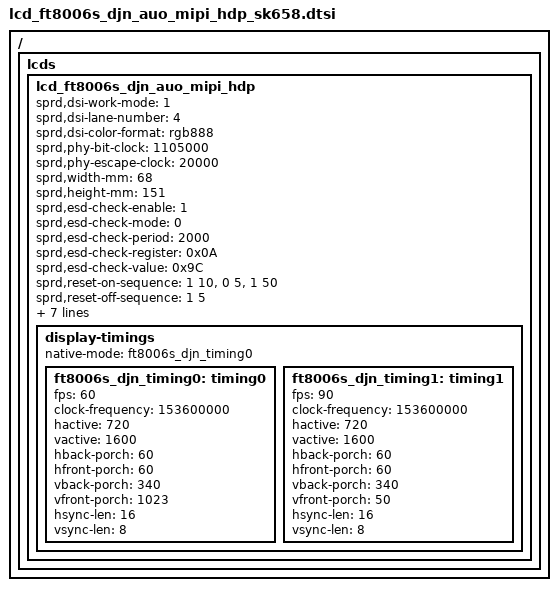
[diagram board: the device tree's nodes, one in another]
/ {
	fragment {
		target-path = "/";
		__overlay__ {
			lcds {
				lcd_ft8006s_djn_auo_mipi_hdp: lcd_ft8006s_djn_auo_mipi_hdp {

					sprd,dsi-work-mode = <1>; /* video burst mode*/
					sprd,dsi-lane-number = <4>;
					sprd,dsi-color-format = "rgb888";

					sprd,phy-bit-clock = <1105000>;	/* kbps */
					sprd,phy-escape-clock = <20000>;/* kHz */

					sprd,width-mm = <68>;
					sprd,height-mm = <151>;
					sprd,esd-check-enable = <1>;
					sprd,esd-check-mode = <0>;
					sprd,esd-check-period = <2000>;
					sprd,esd-check-register = <0x0A>;
					sprd,esd-check-value = <0x9C>;

					sprd,reset-on-sequence = <1 10>, <0 5>, <1 50>;
					sprd,reset-off-sequence = <1 5>;

					sprd,use-dcs-write;

					sprd,initial-command = [
						//-------------  Display Initial Code Setting  -------------------------
						//Stop reload
						23 00 00 02 41 5A 
						//SPI Not LoadFinish
						29 00 00 03 41 5A 24 
						23 00 00 02 90 5A 
						//VCOM
						//29 00 00 03 41 5A 03 
						//29 00 00 03 80 25 01 
						//----------------------LCD initial code start----------------------//
						//Blank 8
						29 00 00 03 41 5A 08 
						29 00 00 05 80 C8 2C 11 00 
						//Blank 9
						29 00 00 03 41 5A 09 
						29 00 00 11 80 00 00 00 00 60 55 4B 01 40 A0 0C 82 20 08 F0 03 
						29 00 00 11 90 99 24 42 0A E3 91 80 F0 AE B9 66 D8 16 21 00 00 
						29 00 00 11 A0 01 55 55 00 A0 4D 06 11 0D 60 5A FF FF 03 A5 E6 
						29 00 00 11 B0 08 C9 16 64 0B 00 00 11 01 60 00 FF FF 03 FF 34 //17
						29 00 00 09 C0 0C 3F 1F 9F 0F 00 08 00 //9
						//Blank 10
						29 00 00 03 41 5A 0A 
						29 00 00 11 80 FF 72 E5 02 11 14 23 35 47 59 5F 90 6E A3 98 66 
						29 00 00 11 90 90 61 5C 4A 38 25 16 0B 11 14 23 35 47 59 5F 90 
						29 00 00 0E A0 6E A3 98 66 90 61 5C 4A 38 25 16 0A 00 //14
						
						23 00 00 03 41 5A 0A 
						29 00 00 11 80 FF 72 E5 02 11 28 38 4A 5D 6F 74 A3 8F C0 7E 51
						29 00 00 11 90 86 5C 58 48 36 26 17 0B 11 28 38 4A 5D 6F 74 A3
						29 00 00 0E A0 8F C0 7E 51 86 5C 58 48 36 26 17 0B 00
						
						//Blank 11
						29 00 00 03 41 5A 0B 
						29 00 00 11 80 00 00 00 00 00 00 60 47 00 00 00 00 00 00 B0 23 
						29 00 00 03 90 15 00 
						//Blank 12
						29 00 00 03 41 5A 0C 
						29 00 00 11 80 BA 68 68 01 32 4B 80 0C 00 60 15 00 50 15 56 51 
						29 00 00 11 90 15 55 61 15 00 60 15 00 50 15 56 51 15 55 61 95 
						29 00 00 11 A0 AB 18 00 05 00 05 00 05 00 49 29 84 52 01 09 00 
						29 00 00 03 B0 00 00 
						//Blank 13
						29 00 00 03 41 5A 0D 
						29 00 00 10 80 F0 B1 71 EF 4B C0 80 5A 00 0E 00 C0 12 00 AF 
						//Blank 14
						29 00 00 03 41 5A 0E 
						29 00 00 0A 80 FF 00 55 55 23 98 76 07 1C 
						//Blank 15
						29 00 00 03 41 5A 0F 
						29 00 00 11 80 B9 0B 70 C0 12 20 64 08 52 51 58 49 03 52 4C 4C 
						29 00 00 11 90 68 68 68 4C 4C 7C 14 00 20 06 C2 00 04 06 0C 40 
						29 00 00 05 A0 00 92 00 04 
						//Blank 16
						29 00 00 03 41 5A 10 
						29 00 00 11 80 00 00 03 E7 1F 17 10 48 80 AA D0 18 30 88 41 8A 
						29 00 00 10 90 39 28 A9 C5 9A 7B F0 07 7E E0 07 7E 20 10 00 
						//Blank 17
						29 00 00 03 41 5A 11 
						29 00 00 11 80 49 77 03 00 CA F3 FF A3 30 08 C4 06 A1 D8 24 18 
						29 00 00 11 90 30 C6 66 C1 80 51 15 CB E5 D2 68 6C 36 1D 04 08 
						29 00 00 11 A0 5A D8 88 60 B0 81 40 1A 1B 48 63 03 B9 00 1C 80 
						29 00 00 11 B0 50 30 00 E0 E1 01 00 28 0E 06 43 D5 4C 55 55 55 
						29 00 00 11 C0 95 88 88 88 88 88 08 08 84 C6 E3 81 00 20 00 21 
						29 00 00 11 D0 42 88 00 00 00 00 00 00 00 31 04 41 06 00 00 00 
						29 00 00 11 E0 00 92 04 00 92 04 00 00 00 00 92 04 00 85 11 0C 
						29 00 00 10 F0 00 00 40 00 00 00 00 5E 4A 55 79 00 08 31 08 
						//Blank 18
						29 00 00 03 41 5A 12 
						29 00 00 11 80 00 00 00 00 00 02 03 00 00 00 00 02 03 00 41 37 
						29 00 00 11 90 F1 E7 00 00 00 00 00 00 00 00 00 00 00 2D 23 05 
						29 00 00 08 A0 FB 08 2D 23 05 FB 0C 
						//Blank 19
						29 00 00 03 41 5A 13 
						29 00 00 11 80 FD 0F 00 0C 00 00 00 A0 01 08 01 1C 44 0C CE E7 
						29 00 00 11 90 62 0E 24 98 AC 21 01 00 D0 93 24 49 06 18 88 13 
						29 00 00 11 A0 88 13 88 13 9F B8 8B 58 02 88 13 88 13 58 02 00 
						29 00 00 0C B0 00 00 00 00 00 00 00 00 00 1B 10 
						//Blank 20
						29 00 00 03 41 5A 14 
						29 00 00 11 80 01 02 41 36 E9 EF F7 FB FD 7E 00 00 00 90 C5 8D 
						29 00 00 11 90 C7 73 20 66 3C 9E 03 1B E0 F1 1C D8 02 8F E7 00 
						29 00 00 11 A0 00 00 00 00 00 00 00 00 00 00 00 00 00 00 00 00 
						29 00 00 11 B0 00 00 00 00 00 00 10 00 00 64 32 26 2B 00 40 A1 
						29 00 00 11 C0 50 F8 33 7A B8 91 51 1C 7F 45 0F 37 32 8A E3 8F 
						29 00 00 11 D0 E8 E1 46 46 71 FC 0D 3D DC C8 28 8E 3F A1 87 1B 
						29 00 00 11 E0 19 C5 F1 17 F4 70 23 A3 38 FE 80 1E 6E 64 14 C7 
						29 00 00 11 F0 2F D0 C3 8D 8C E2 18 01 BF DF 08 00 00 00 00 00 
						//Blank 21
						29 00 00 03 41 5A 15 
						29 00 00 11 80 00 00 00 00 00 00 00 00 00 00 00 00 52 D9 E0 F7 
						29 00 00 11 90 A3 00 20 CB 06 EA F1 00 00 00 00 00 00 00 00 00 
						29 00 00 11 A0 00 00 00 00 00 00 00 00 00 00 00 00 00 00 00 00 
						29 00 00 11 B0 00 00 00 00 00 00 00 00 00 00 00 00 00 D3 A4 28 
						29 00 00 11 C0 10 34 4D A4 05 14 81 21 1C 03 82 4C D3 34 4D 49 
						29 00 00 11 D0 32 4D 10 3C DA A7 68 86 25 48 2C CB 34 4D D3 B4 
						29 00 00 11 E0 2C 10 34 CD A4 0D 96 A1 29 9E 43 92 4C D3 34 4D 
						29 00 00 11 F0 08 32 4D 10 34 5A 87 60 04 05 40 28 CA 34 4D 12 
						//Blank 22
						29 00 00 03 41 5A 16 
						29 00 00 11 80 02 02 02 02 00 00 00 00 00 00 00 00 00 00 00 00 
						29 00 00 07 90 00 00 00 00 F0 20 
						//Blank 24
						29 00 00 03 41 5A 18 
						29 00 00 11 80 04 FF 00 80 80 00 04 20 00 01 08 40 00 02 10 80 
						29 00 00 03 90 00 04 
						//Blank 25
						29 00 00 03 41 5A 19 
						29 00 00 11 80 C0 AF A3 9B 92 8D 8A 86 84 83 82 81 00 50 F6 CF 
						29 00 00 11 90 FC 2F F3 EF CF BF 0F FF AF B5 71 0E 6C 4A 69 08 
						29 00 00 05 A0 05 05 02 00 
						//Blank 26
						29 00 00 03 41 5A 1A 
						29 00 00 11 80 00 04 08 0C 00 10 14 18 1C 00 20 28 30 38 00 40 
						29 00 00 11 90 48 50 58 00 60 68 70 78 00 80 88 90 98 00 A0 A8 
						29 00 00 11 A0 B0 B8 00 C0 C8 D0 D8 00 E0 E8 F0 F8 00 FC FE FF 
						29 00 00 11 B0 00 00 04 08 0C 00 10 14 18 1C 00 20 28 30 38 00 
						29 00 00 11 C0 40 48 50 58 00 60 68 70 78 00 80 88 90 98 00 A0 
						29 00 00 11 D0 A8 B0 B8 00 C0 C8 D0 D8 00 E0 E8 F0 F8 00 FC FE 
						29 00 00 11 E0 FF 00 00 04 08 0C 00 10 14 18 1C 00 20 28 30 38 
						29 00 00 11 F0 00 40 48 50 58 00 60 68 70 78 00 80 88 90 98 00 
						//Blank 27
						29 00 00 03 41 5A 1B 
						29 00 00 11 80 A0 A8 B0 B8 00 C0 C8 D0 D8 00 E0 E8 F0 F8 00 FC 
						29 00 00 05 90 FE FF 00 00 
						//Blank 32
						29 00 00 03 41 5A 20 
						29 00 00 08 80 84 00 02 14 00 00 00 
						//Blank 34
						29 00 00 03 41 5A 22 
						29 00 00 0E 80 2D D3 00 55 55 55 55 55 55 55 55 9F 00 
						//Blank 35
						29 00 00 03 41 5A 23 
						29 00 00 11 80 00 00 00 05 00 00 00 00 00 00 00 00 00 00 00 00 
						29 00 00 0D 90 FF 0F 00 00 00 03 00 00 00 FF 07 35 
						//Blank 36
						29 00 00 03 41 5A 24 
						29 00 00 11 80 00 03 00 FF FF 20 00 00 00 00 00 00 00 00 68 7A 
						29 00 00 11 90 5A 5A 5A 55 00 00 00 00 00 00 00 00 00 00 00 00 
						//----------------------LCD initial code End----------------------//
						//SPI FINISH
						23 00 00 02 42 24 
						23 00 00 02 90 00 
						//Blank select 2F 
						29 00 00 03 41 5A 2F 
						23 00 00 02 19 01 
						//INT CANCEL
						23 00 00 02 4C 03 

						13 78 00 01 11 
						//delayms_pc(120) 
						13 14 00 01 29			
						/*-------------  Display Initial Setting end -------------------------*/
					];

					sprd,sleep-in-command = [
						13 32 00 01 28
						13 32 00 01 10
						23 00 00 02 17 5A
						23 96 00 02 18 5A
					];

					sprd,sleep-out-command = [
						13 78 00 01 11
						13 14 00 01 29
					];

					display-timings {
						native-mode = <&ft8006s_djn_timing0>;
						ft8006s_djn_timing0: timing0 {
							fps = <60>;
							clock-frequency = <153600000>;
							hactive = <720>;
							vactive = <1600>;
							hback-porch = <60>;
							hfront-porch = <60>;
							vback-porch = <340>;
							vfront-porch = <1023>;//1023
							hsync-len = <16>;
							vsync-len = <8>;
						};
						ft8006s_djn_timing1: timing1 {
							fps = <90>;
							clock-frequency = <153600000>;
							hactive = <720>;
							vactive = <1600>;
							hback-porch = <60>;
							hfront-porch = <60>;
							vback-porch = <340>;
							vfront-porch = <50>;//1023
							hsync-len = <16>;
							vsync-len = <8>;
						};
					};
				};
			};
		};
	};
};
